VERSION ""

NS_ :

BS_:

BU_: ABS DoorController CentralLocking Handbrake

VAL_TABLE_ WheelDirection 2 "Reverse" 1 "Forward" 0 "Stopped" ;
VAL_TABLE_ SlidingDoorState 1 "Closed" 0 "Open" ;

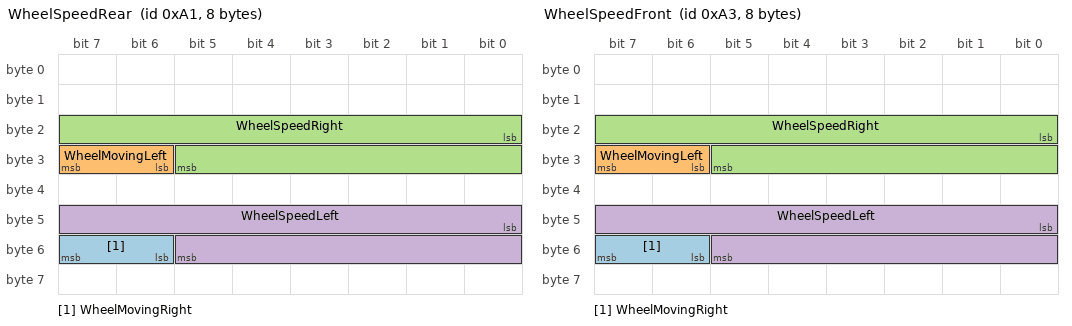
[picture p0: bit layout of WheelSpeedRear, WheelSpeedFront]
BO_ 161 WheelSpeedRear: 8 ABS
 SG_ WheelMovingRight : 54|2@1+ (1,0) [0|3] "" Vector__XXX
 SG_ WheelMovingLeft : 30|2@1+ (1,0) [0|3] "" Vector__XXX
 SG_ WheelSpeedRight : 16|14@1+ (0.068355,0) [0|1119.859965] "km/h" Vector__XXX
 SG_ WheelSpeedLeft : 40|14@1+ (0.068355,0) [0|1119.859965] "km/h" Vector__XXX

BO_ 163 WheelSpeedFront: 8 ABS
 SG_ WheelMovingRight : 54|2@1+ (1,0) [0|3] "" Vector__XXX
 SG_ WheelMovingLeft : 30|2@1+ (1,0) [0|3] "" Vector__XXX
 SG_ WheelSpeedRight : 16|14@1+ (0.068355,0) [0|1119.859965] "km/h" Vector__XXX
 SG_ WheelSpeedLeft : 40|14@1+ (0.068355,0) [0|1119.859965] "km/h" Vector__XXX

BO_ 933 SlidingDoorFrame: 8 DoorController
 SG_ SlidingDoorState : 12|1@1+ (1,0) [0|1] "" Vector__XXX

BO_ 919 DriverDoorFrame: 8 DoorController
 SG_ DriverDoorState : 12|2@1+ (1,0) [0|3] "" Vector__XXX

BO_ 923 PassengerDoorFrame: 8 DoorController
 SG_ PassengerDoorState : 12|2@1+ (1,0) [0|3] "" Vector__XXX

BO_ 775 CentralLockingFrame: 8 CentralLocking
 SG_ CentralLockingFlagsB3 : 24|8@1+ (1,0) [0|0] "" Vector__XXX

BO_ 794 DriverWindowFrame: 8 DoorController
 SG_ DriverWindowClosed : 13|1@1+ (1,0) [0|1] "" Vector__XXX

BO_ 800 PassengerWindowFrame: 8 DoorController
 SG_ PassengerWindowClosed : 13|1@1+ (1,0) [0|1] "" Vector__XXX

BO_ 849 RearDoorFrame: 8 DoorController
 SG_ RearDoorState : 0|2@1+ (1,0) [0|3] "" Vector__XXX

BO_ 885 OdometerFrame: 8 Vector__XXX
 SG_ Odometer : 16|32@1+ (0.01,0) [0|42949672.95] "km" Vector__XXX

BO_ 549 HandbrakeFrame: 8 Handbrake
 SG_ HandbrakeState : 16|3@1+ (1,0) [0|0] "" Vector__XXX

CM_ SG_ 161 WheelMovingRight "Wheel direction, right";
CM_ SG_ 161 WheelMovingLeft "Wheel direction, left";
CM_ SG_ 161 WheelSpeedRight "Wheel speed, right, km/h";
CM_ SG_ 161 WheelSpeedLeft "Wheel speed, left, km/h";
CM_ SG_ 163 WheelMovingRight "Wheel direction, right";
CM_ SG_ 163 WheelMovingLeft "Wheel direction, left";
CM_ SG_ 163 WheelSpeedRight "Wheel speed, right, km/h";
CM_ SG_ 163 WheelSpeedLeft "Wheel speed, left, km/h";
CM_ SG_ 933 SlidingDoorState "Sliding door state";
CM_ SG_ 919 DriverDoorState "Driver door state";
CM_ SG_ 923 PassengerDoorState "Passenger door state";
CM_ BO_ 775 "50Hz rate, 10 frames transmitted on state changes";
CM_ SG_ 775 CentralLockingFlagsB3 "Central locking state";
CM_ SG_ 794 DriverWindowClosed "Driver window closed flag. Observed 1 when closed, 0 when open. Raw bytes 1-2 little-endian were 0x01e8 closed and 0x2148/0x224a open.";
CM_ SG_ 800 PassengerWindowClosed "Passenger window closed flag. Observed 1 when closed, 0 when open. Raw bytes 1-2 little-endian were 0x01e8 closed and 0x0148/0x2148/0x224a/0x22dc open.";
CM_ SG_ 849 RearDoorState "Rear door state";
CM_ SG_ 885 Odometer "Odometer reading";
CM_ SG_ 549 HandbrakeState "Handbrake state";
BA_DEF_  "BusType" STRING ;
BA_DEF_DEF_  "BusType" "CAN";
VAL_ 161 WheelMovingRight 2 "Reverse" 1 "Forward" 0 "Stopped" ;
VAL_ 161 WheelMovingLeft 2 "Reverse" 1 "Forward" 0 "Stopped" ;
VAL_ 163 WheelMovingRight 2 "Reverse" 1 "Forward" 0 "Stopped" ;
VAL_ 163 WheelMovingLeft 2 "Reverse" 1 "Forward" 0 "Stopped" ;
VAL_ 933 SlidingDoorState 1 "Closed" 0 "Open" ;
VAL_ 919 DriverDoorState 2 "Open" 1 "Closed" ;
VAL_ 923 PassengerDoorState 2 "Open" 1 "Closed" ;
VAL_ 794 DriverWindowClosed 1 "Closed" 0 "Open" ;
VAL_ 800 PassengerWindowClosed 1 "Closed" 0 "Open" ;
VAL_ 775 CentralLockingFlagsB3 0 "Idle" 1 "Interior_button_lock_request" 10 "Interior_button_unlock_request" 21 "Keyfob_lock_request_(doors_open)" 85 "Keyfob_lock_request_(doors_closed)" 170 "Keyfob_unlock_request" ;
VAL_ 849 RearDoorState 1 "RearDoorClosed" 2 "RearDoorOpen" ;
VAL_ 549 HandbrakeState 3 "HandbrakeOn" 4 "HandbrakeOff" ;
